// Description:

// Created:

// Author:

// Version:

// Vehicle Project:

LIN_description_file;
LIN_protocol_version = "2.1";
LIN_language_version = "2.1";
LIN_speed = 19.2 kbps;

Nodes {
  Master: BCM, 10 ms, 0.1 ms ;
  Slaves: LFWL, RFWL, LRWL, RRWL;
}
Signals {
  L_BCM_WdwEnable: 1, 0, BCM, LFWL, RFWL, LRWL, RRWL ; //Enable windows movement
  L_BCM_LockCommand: 2, 0, BCM, LFWL, RFWL, LRWL, RRWL ; //Lock Command
  L_BCM_GlobalClose: 2, 0, BCM, LFWL, RFWL, LRWL, RRWL ; //close all windows
  L_BCM_GlobalOpen: 2, 0, BCM, LFWL, RFWL, LRWL, RRWL ; //Open all windows
  L_BCM_ChildLockSt: 1, 0, BCM, LFWL, RFWL, LRWL, RRWL ; //window status of child lock
  L_Pas_Wdw_CenterSwitch: 3, 0, BCM, LFWL, RFWL, LRWL, RRWL ; //Center switch status of passenger window
  L_RLD_Wdw_CenterSwitch: 3, 0, BCM, LFWL, RFWL, LRWL, RRWL ; //Center switch status of Rear Left window
  L_RRD_Wdw_CenterSwitch: 3, 0, BCM, LFWL, RFWL, LRWL, RRWL ; //Center switch status of Rear Right window
  L_Drv_ControlCommand: 7, 127, BCM, LFWL, RFWL, LRWL, RRWL ; //driver window control command
  L_Pas_ControlCommand: 7, 127, BCM, LFWL, RFWL, LRWL, RRWL ; //passenger window control command
  L_RLD_ControlCommand: 7, 127, BCM, LFWL, RFWL, LRWL, RRWL ; //Rear Left window control command
  L_RRD_ControlCommand: 7, 127, BCM, LFWL, RFWL, LRWL, RRWL ; //Rear Right window control command
  L_EMS_EngStatus: 3, 0, BCM, LFWL, RFWL, LRWL, RRWL ; //Engine running status

  L_PEPS_PowerModeValidity: 2, 0, BCM, LFWL, RFWL, LRWL, RRWL; //PEPS Power Distribution StatusValidity bit
  L_PEPS_PowerMode: 3, 0, BCM, LFWL, RFWL, LRWL, RRWL ; //PEPS Power Distribution Status
  L_BCM_VehicleSpeed: 13, 0, BCM, LFWL, RFWL, LRWL, RRWL ; //VehicleSpeed
  L_BCM_OutdoorTemp: 8, 120, BCM, LFWL, RFWL, LRWL, RRWL ; //outdoor ambient temperature
  L_BCM_VehicleType_Reserved: 3, 7, BCM, LFWL, RFWL, LRWL, RRWL ; //With this value the vehicle type is coded

  L_Steer_Whl_Type_Reserved: 2, 3, BCM, LFWL, RFWL, LRWL, RRWL ; //With this value, the steering type is transmitted for the solar sensors. The value is required for the air-conditioning system

  L_Drv_Wdw_Running_Sts: 3, 0, LFWL, BCM ; //Running status of driver window
  L_Drv_Wdw_CenterSwitch: 3, 0, LFWL, BCM ; //Center switch status of driver window
  L_Drv_Wdw_PositionSts: 2, 0, LFWL, BCM ; //Position status of driver window
  L_Drv_Val_Wdw_Opened: 7, 127, LFWL, BCM ; //Window Opened Value
  L_Drv_HALL_Error: 1, 0, LFWL, BCM ; //Hall Sensor Error
  L_Drv_Motor_Relay_Error: 1, 0, LFWL, BCM ; //Motor relay Error
  L_Drv_OverHeat_Protect: 1, 0, LFWL, BCM ; //OverHeat Protect
  L_Drv_Wdw_Init: 1, 0, LFWL, BCM ; //ECU Initialization
  DDAPWL_01_LIN_Response_Error: 1, 0, LFWL, BCM ; //LIN Communication ERROR
  L_Drv_UnderVoltage: 1, 0, LFWL, BCM ; //Driver window under volt
  L_Drv_OverVoltage: 1, 0, LFWL, BCM ; //Driver window over volt
  L_Drv_Wdw_OD_Sts: 1, 0, LFWL, BCM ; //Obstacle detection status
  L_Drv_Wdw_Obs_InhibitSts: 1, 0, LFWL, BCM ; //Obstacle inhibit status
  L_Pas_Wdw_Running_Sts: 3, 0, RFWL, BCM ; //Running status of passager window
  L_Pas_Wdw_LocalSwitch: 3, 0, RFWL, BCM ; //Local switch status of passager window
  L_Pas_Wdw_PositionSts: 2, 0, RFWL, BCM ; //Position status of passager window
  L_Pas_Val_Wdw_Opened: 7, 127, RFWL, BCM ; //Window Opened Value
  L_Pas_HALL_Error: 1, 0, RFWL, BCM ; //Hall Sensor Error
  L_Pas_Motor_Relay_Error: 1, 0, RFWL, BCM ; //Motor relay Error
  L_Pas_OverHeat_Protect: 1, 0, RFWL, BCM ; //OverHeat Protect
  L_Pas_Wdw_Init: 1, 0, RFWL, BCM ; //ECU Initialization
  PDAPWL_01_LIN_Response_Error: 1, 0, RFWL, BCM ; //LIN Communication ERROR
  L_Pas_UnderVoltage: 1, 0, RFWL, BCM ; //Passenger window under volt
  L_Pas_OverVoltage: 1, 0, RFWL, BCM ; //Passenger window over volt
  L_Pas_Wdw_OD_Sts: 1, 0, RFWL, BCM ; //Obstacle detection status
  L_Pas_Wdw_Obs_InhibitSts: 1, 0, RFWL, BCM ; //Obstacle inhibit status
  L_RLD_Wdw_Running_Sts: 3, 0, LRWL, BCM ; //Running status of Rear Left window
  L_RLD_Wdw_LocalSwitch: 3, 0, LRWL, BCM ; //Local switch status of Rear Left window
  L_RLD_Wdw_PositionSts: 2, 0, LRWL, BCM ; //Position status of Rear Left window
  L_RLD_Val_Wdw_Opened: 7, 127, LRWL, BCM ; //Window Opened Value
  L_RLD_HALL_Error: 1, 0, LRWL, BCM ; //Hall Sensor Error
  L_RLD_Motor_Relay_Error: 1, 0, LRWL, BCM ; //Motor relay Error
  L_RLD_OverHeat_Protect: 1, 0, LRWL, BCM ; //OverHeat Protect
  L_RLD_Wdw_Init: 1, 0, LRWL, BCM ; //ECU Initialization
  RLAPWL_01_LIN_Response_Error: 1, 0, LRWL, BCM ; //LIN Communication ERROR
  L_RLUnderVoltage: 1, 0, LRWL, BCM ; //Rear Left window under volt
  L_RLOverVoltage: 1, 0, LRWL, BCM ; //Rear Left window over volt
  L_RLD_Wdw_OD_Sts: 1, 0, LRWL, BCM ; //Obstacle detection status
  L_RLD_Wdw_Obs_InhibitSts: 1, 0, LRWL, BCM ; //Obstacle inhibit status
  L_RRD_Wdw_Running_Sts: 3, 0, RRWL, BCM ; //Running status of Rear Right window
  L_RRD_Wdw_LocalSwitch: 3, 0, RRWL, BCM ; //Local switch status of Rear Right window
  L_RRD_Wdw_PositionSts: 2, 0, RRWL, BCM ; //Position status of Rear Right window
  L_RRD_Val_Wdw_Opened: 7, 127, RRWL, BCM ; //Window Opened Value
  L_RRD_SHALL_Error: 1, 0, RRWL, BCM ; //Hall Sensor Error
  L_RRD_SMotor_Relay_Error: 1, 0, RRWL, BCM ; //Motor relay Error
  L_RRD_SOverHeat_Protect: 1, 0, RRWL, BCM ; //OverHeat Protect
  L_RRD_Wdw_Init: 1, 0, RRWL, BCM ; //ECU Initialization
  RRAPWL_01_LIN_Response_Error: 1, 0, RRWL, BCM ; //LIN Communication ERROR
  L_RRUnderVoltage: 1, 0, RRWL, BCM ; //Rear Right window under volt
  L_RROverVoltage: 1, 0, RRWL, BCM ; //Rear Right window over volt
  L_RRD_Wdw_OD_Sts: 1, 0, RRWL, BCM ; //Obstacle detection status
  L_RRD_Wdw_Obs_InhibitSts: 1, 0, RRWL, BCM ; //Obstacle inhibit status
}

Frames {
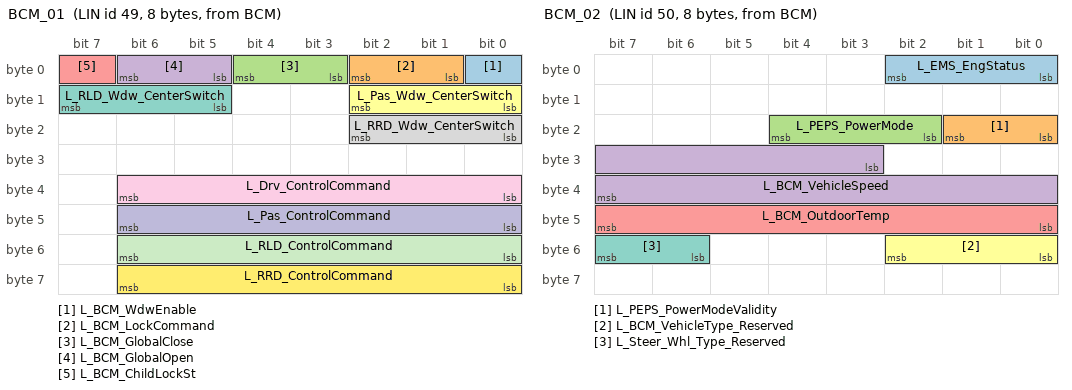
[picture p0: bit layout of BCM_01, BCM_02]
  BCM_01: 49, BCM, 8 {
    L_BCM_WdwEnable, 0 ;
    L_BCM_LockCommand, 1 ;
    L_BCM_GlobalClose, 3 ;
    L_BCM_GlobalOpen, 5 ;
    L_BCM_ChildLockSt, 7 ;
    L_Pas_Wdw_CenterSwitch, 8 ;
    L_RLD_Wdw_CenterSwitch, 13 ;
    L_RRD_Wdw_CenterSwitch, 16 ;
    L_Drv_ControlCommand, 32 ;
    L_Pas_ControlCommand, 40 ;
    L_RLD_ControlCommand, 48 ;
    L_RRD_ControlCommand, 56 ;
  }
  BCM_02: 50, BCM, 8 {
    L_EMS_EngStatus, 0 ;

    L_PEPS_PowerModeValidity, 16 ;
    L_PEPS_PowerMode, 18 ;

    L_BCM_VehicleSpeed, 27 ;
    L_BCM_OutdoorTemp, 40 ;
    L_BCM_VehicleType_Reserved, 48 ;

    L_Steer_Whl_Type_Reserved, 54 ;

  }

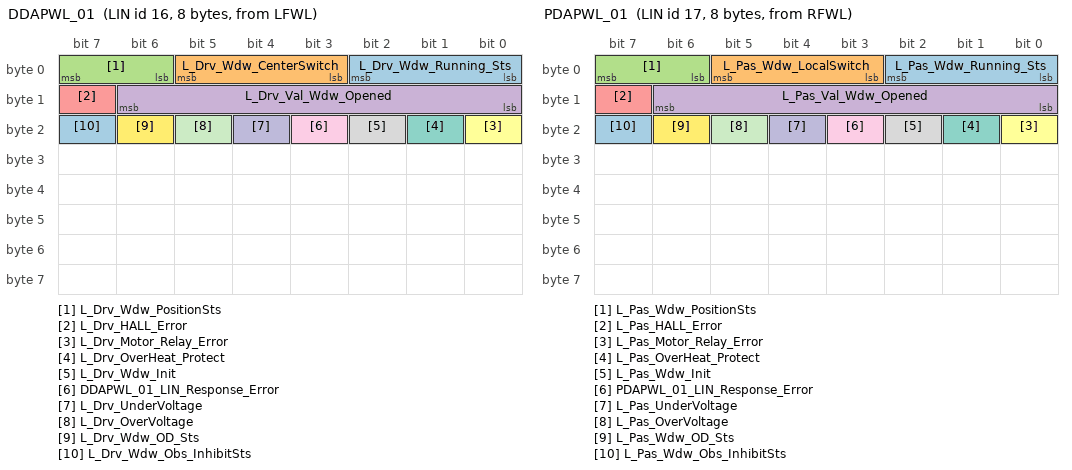
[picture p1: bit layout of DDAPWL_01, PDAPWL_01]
  DDAPWL_01: 16, LFWL, 8 {
    L_Drv_Wdw_Running_Sts, 0 ;
    L_Drv_Wdw_CenterSwitch, 3 ;
    L_Drv_Wdw_PositionSts, 6 ;
    L_Drv_Val_Wdw_Opened, 8 ;
    L_Drv_HALL_Error, 15 ;
    L_Drv_Motor_Relay_Error, 16 ;
    L_Drv_OverHeat_Protect, 17 ;
    L_Drv_Wdw_Init, 18 ;
    DDAPWL_01_LIN_Response_Error, 19 ;
    L_Drv_UnderVoltage, 20 ;
    L_Drv_OverVoltage, 21 ;
    L_Drv_Wdw_OD_Sts, 22 ;
    L_Drv_Wdw_Obs_InhibitSts, 23 ;
  }
  PDAPWL_01: 17, RFWL, 8 {
    L_Pas_Wdw_Running_Sts, 0 ;
    L_Pas_Wdw_LocalSwitch, 3 ;
    L_Pas_Wdw_PositionSts, 6 ;
    L_Pas_Val_Wdw_Opened, 8 ;
    L_Pas_HALL_Error, 15 ;
    L_Pas_Motor_Relay_Error, 16 ;
    L_Pas_OverHeat_Protect, 17 ;
    L_Pas_Wdw_Init, 18 ;
    PDAPWL_01_LIN_Response_Error, 19 ;
    L_Pas_UnderVoltage, 20 ;
    L_Pas_OverVoltage, 21 ;
    L_Pas_Wdw_OD_Sts, 22 ;
    L_Pas_Wdw_Obs_InhibitSts, 23 ;
  }
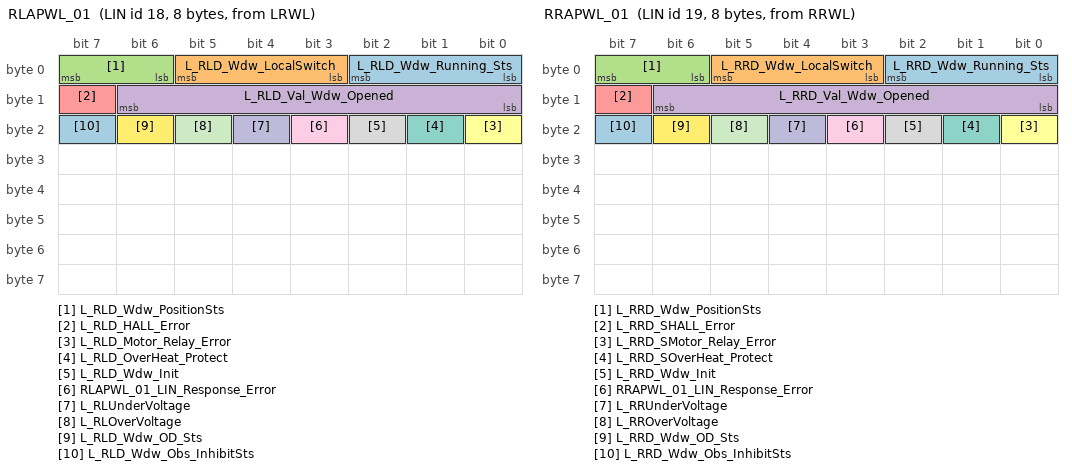
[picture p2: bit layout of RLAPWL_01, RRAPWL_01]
  RLAPWL_01: 18, LRWL, 8 {
    L_RLD_Wdw_Running_Sts, 0 ;
    L_RLD_Wdw_LocalSwitch, 3 ;
    L_RLD_Wdw_PositionSts, 6 ;
    L_RLD_Val_Wdw_Opened, 8 ;
    L_RLD_HALL_Error, 15 ;
    L_RLD_Motor_Relay_Error, 16 ;
    L_RLD_OverHeat_Protect, 17 ;
    L_RLD_Wdw_Init, 18 ;
    RLAPWL_01_LIN_Response_Error, 19 ;
    L_RLUnderVoltage, 20 ;
    L_RLOverVoltage, 21 ;
    L_RLD_Wdw_OD_Sts, 22 ;
    L_RLD_Wdw_Obs_InhibitSts, 23 ;
  }
  RRAPWL_01: 19, RRWL, 8 {
    L_RRD_Wdw_Running_Sts, 0 ;
    L_RRD_Wdw_LocalSwitch, 3 ;
    L_RRD_Wdw_PositionSts, 6 ;
    L_RRD_Val_Wdw_Opened, 8 ;
    L_RRD_SHALL_Error, 15 ;
    L_RRD_SMotor_Relay_Error, 16 ;
    L_RRD_SOverHeat_Protect, 17 ;
    L_RRD_Wdw_Init, 18 ;
    RRAPWL_01_LIN_Response_Error, 19 ;
    L_RRUnderVoltage, 20 ;
    L_RROverVoltage, 21 ;
    L_RRD_Wdw_OD_Sts, 22 ;
    L_RRD_Wdw_Obs_InhibitSts, 23 ;
  }
}

Node_attributes {
  LFWL{
    LIN_protocol = "2.1" ;
    configured_NAD = 0x10 ;
    product_id = 0x0, 0x0, 0 ;
    response_error = DDAPWL_01_LIN_Response_Error ;
    P2_min = 50 ms ;
    ST_min = 0 ms ;
    N_As_timeout = 1000 ms ;
    N_Cr_timeout = 1000 ms ;
    configurable_frames {
      DDAPWL_01;
      BCM_01 ;
      BCM_02 ;
    }
  }
  LRWL{
    LIN_protocol = "2.1" ;
    configured_NAD = 0x12 ;
    product_id = 0x0, 0x0, 0 ;
    response_error = RLAPWL_01_LIN_Response_Error ;
    P2_min = 50 ms ;
    ST_min = 0 ms ;
    N_As_timeout = 1000 ms ;
    N_Cr_timeout = 1000 ms ;
    configurable_frames {
      RLAPWL_01 ;
      BCM_01;
      BCM_02;
    }
  }
  RFWL{
    LIN_protocol = "2.1" ;
    configured_NAD = 0x11 ;
    product_id = 0x0, 0x0, 0 ;
    response_error = PDAPWL_01_LIN_Response_Error ;
    P2_min = 50 ms ;
    ST_min = 0 ms ;
    N_As_timeout = 1000 ms ;
    N_Cr_timeout = 1000 ms ;
    configurable_frames {
      PDAPWL_01 ;
      BCM_01 ;
      BCM_02 ;
    }
  }
  RRWL{
    LIN_protocol = "2.1" ;
    configured_NAD = 0x13 ;
    product_id = 0x0, 0x0, 0 ;
    response_error = RRAPWL_01_LIN_Response_Error ;
    P2_min = 50 ms ;
    ST_min = 0 ms ;
    N_As_timeout = 1000 ms ;
    N_Cr_timeout = 1000 ms ;
    configurable_frames {
      RRAPWL_01;
      BCM_01 ;
      BCM_02 ;
    }
  }

}

Schedule_tables {
Dynamic {
    BCM_01 delay 10 ms ;//49 31
    BCM_02 delay 30 ms ;//50 32

    DDAPWL_01 delay 10 ms ;//16 10
    BCM_01 delay 10 ms ;//49 31
    BCM_02 delay 10 ms ;//50 32
    PDAPWL_01 delay 10 ms ;//17 11
    RLAPWL_01 delay 10 ms ;//18 12
    RRAPWL_01 delay 10 ms ;//19 13
  }
}
Signal_encoding_types {
  L_BCM_WdwEnable {
    physical_value, 0x0, 0x1, 1, 0, "bit" ;
    logical_value, 0, "Inhibit" ;
    logical_value, 1, "Normal" ;
  }
  L_BCM_LockCommand {
    physical_value, 0x0, 0x3, 1, 0, "bit" ;
    logical_value, 0, "No command" ;
    logical_value, 1, "All door lock" ;
    logical_value, 2, "All door unlock" ;
    logical_value, 3, "Reserved" ;
  }
  L_BCM_GlobalClose {
    physical_value, 0x0, 0x3, 1, 0, "bit" ;
    logical_value, 0, "No action" ;
    logical_value, 1, "Global Close" ;
    logical_value, 2, "Reserved" ;
    logical_value, 3, "Reserved" ;
  }
  L_BCM_GlobalOpen {
    physical_value, 0x0, 0x3, 1, 0, "bit" ;
    logical_value, 0, "No action" ;
    logical_value, 1, "Global Open" ;
    logical_value, 2, "Reserved" ;
    logical_value, 3, "Reserved" ;
  }
  L_BCM_ChildLockSt {
    physical_value, 0x0, 0x1, 1, 0, "bit" ;
    logical_value, 0, "Unlock" ;
    logical_value, 1, "Lock" ;
  }
  L_Pas_Wdw_CenterSwitch {
    physical_value, 0x0, 0x7, 1, 0, "bit" ;
    logical_value, 0, "Inactive" ;
    logical_value, 1, "Manual Up" ;
    logical_value, 2, "Manual Down" ;
    logical_value, 3, "Auto Up" ;
    logical_value, 4, "Auto Down" ;
    logical_value, 5, "Reserved" ;
    logical_value, 6, "Reserved" ;
    logical_value, 7, "Error" ;
  }
  L_RLD_Wdw_CenterSwitch {
    physical_value, 0x0, 0x7, 1, 0, "bit" ;
    logical_value, 0, "Inactive" ;
    logical_value, 1, "Manual Up" ;
    logical_value, 2, "Manual Down" ;
    logical_value, 3, "Auto Up" ;
    logical_value, 4, "Auto Down" ;
    logical_value, 5, "Reserved" ;
    logical_value, 6, "Reserved" ;
    logical_value, 7, "Error" ;
  }
  L_RRD_Wdw_CenterSwitch {
    physical_value, 0x0, 0x7, 1, 0, "bit" ;
    logical_value, 0, "Inactive" ;
    logical_value, 1, "Manual Up" ;
    logical_value, 2, "Manual Down" ;
    logical_value, 3, "Auto Up" ;
    logical_value, 4, "Auto Down" ;
    logical_value, 5, "Reserved" ;
    logical_value, 6, "Reserved" ;
    logical_value, 7, "Error" ;
  }
  L_Drv_ControlCommand {
    physical_value, 0x0, 0x64, 1, 0, "%" ;
    logical_value, 127, "No Request" ;
  }
  L_Pas_ControlCommand {
    physical_value, 0x0, 0x64, 1, 0, "%" ;
    logical_value, 127, "No Request" ;
  }
  L_RLD_ControlCommand {
    physical_value, 0x0, 0x64, 1, 0, "%" ;
    logical_value, 127, "No Request" ;
  }
  L_RRD_ControlCommand {
    physical_value, 0x0, 0x64, 1, 0, "%" ;
    logical_value, 127, "No Request" ;
  }
  L_EMS_EngStatus {
    physical_value, 0x0, 0x7, 1, 0, "bit" ;
    logical_value, 0, "Engine Stop" ;
    logical_value, 1, "Cranking" ;
    logical_value, 2, "Reserved" ;
    logical_value, 3, "Running" ;
    logical_value, 4, "Reserved" ;
    logical_value, 5, "Reserved" ;
    logical_value, 6, "Reserved" ;
    logical_value, 7, "Fault" ;
  }

  L_PEPS_PowerModeValidity {
    physical_value, 0x0, 0x3, 1, 0, "bit" ;
    logical_value, 0, "Not available" ;
    logical_value, 1, "Invalid" ;
    logical_value, 2, "Valid" ;
    logical_value, 3, "Reserved" ;
  }
  L_PEPS_PowerMode {
    physical_value, 0x0, 0x7, 1, 0, "bit" ;
    logical_value, 0, "OFF" ;
    logical_value, 1, "ACC" ;
    logical_value, 2, "ON" ;
    logical_value, 3, "Reserved" ;
    logical_value, 4, "START" ;
  }

  L_BCM_VehicleSpeed {
    physical_value, 0x0, 0x1FFE, 0.05625, 0, "KPH" ;
    logical_value, 8191, "Invalid" ;
  }
  L_BCM_OutdoorTemp {
    physical_value, 0x0, 0xC8, 0.5, -40, "°„C" ;
    logical_value, 201, "Invalid" ;
  }
  L_BCM_VehicleType_Reserved {
    physical_value, 0x0, 0x7, 1, 0, "bit" ;
    logical_value, 0, "GC-1" ;
    logical_value, 1, "NL-1" ;
    logical_value, 2, "KC-1" ;
    logical_value, 3, "FE-5/7" ;
    logical_value, 4, "KC-2" ;
    logical_value, 5, "FE-6" ;
    logical_value, 6, "Reserved" ;
    logical_value, 7, "Invalid" ;
  }

  L_Steer_Whl_Type_Reserved {
    physical_value, 0x0, 0x3, 1, 0, "bit" ;
    logical_value, 0, "Left-hand drive" ;
    logical_value, 1, "Right-hand drive" ;
    logical_value, 2, "Reserved" ;
    logical_value, 3, "Invalid" ;
  }

  L_Drv_Wdw_Running_Sts {
    physical_value, 0x0, 0x7, 1, 0, "bit" ;
    logical_value, 0, "Window stop" ;
    logical_value, 1, "Manual Up" ;
    logical_value, 2, "Manual Down" ;
    logical_value, 3, "Auto Up" ;
    logical_value, 4, "Auto Down" ;
  }
  L_Drv_Wdw_CenterSwitch {
    physical_value, 0x0, 0x7, 1, 0, "bit" ;
    logical_value, 0, "Inactive" ;
    logical_value, 1, "Manual Up" ;
    logical_value, 2, "Manual Down" ;
    logical_value, 3, "Auto Up" ;
    logical_value, 4, "Auto Down" ;
    logical_value, 5, "Reserved" ;
    logical_value, 6, "Reserved" ;
    logical_value, 7, "Error" ;
  }
  L_Drv_Wdw_PositionSts {
    physical_value, 0x0, 0x3, 1, 0, "bit" ;
    logical_value, 0, "Middle position" ;
    logical_value, 1, "Complete Open" ;
    logical_value, 2, "Complete Close" ;
    logical_value, 3, "Invalid" ;
  }
  L_Drv_Val_Wdw_Opened {
    physical_value, 0x0, 0x64, 1, 0, "%" ;
    logical_value, 127, "Invalid" ;
  }
  L_Drv_HALL_Error {
    physical_value, 0x0, 0x1, 1, 0, "bit" ;
    logical_value, 0, "Normal" ;
    logical_value, 1, "Error" ;
  }
  L_Drv_Motor_Relay_Error {
    physical_value, 0x0, 0x1, 1, 0, "bit" ;
    logical_value, 0, "Normal" ;
    logical_value, 1, "Error" ;
  }
  L_Drv_OverHeat_Protect {
    physical_value, 0x0, 0x1, 1, 0, "bit" ;
    logical_value, 0, "Inactive" ;
    logical_value, 1, "Active" ;
  }
  L_Drv_Wdw_Init {
    physical_value, 0x0, 0x1, 1, 0, "bit" ;
    logical_value, 0, "Window init incomplete" ;
    logical_value, 1, "Window init complete" ;
  }
  DDAPWL_01_LIN_Response_Error {
    physical_value, 0x0, 0x1, 1, 0, "bit" ;
    logical_value, 0, "Normal" ;
    logical_value, 1, "Error" ;
  }
  L_Drv_UnderVoltage {
    physical_value, 0x0, 0x1, 1, 0, "bit" ;
    logical_value, 0, "Normal" ;
    logical_value, 1, "UnderVoltage" ;
  }
  L_Drv_OverVoltage {
    physical_value, 0x0, 0x1, 1, 0, "bit" ;
    logical_value, 0, "Normal" ;
    logical_value, 1, "OverVoltage" ;
  }
  L_Drv_Wdw_OD_Sts {
    physical_value, 0x0, 0x1, 1, 0, "bit" ;
    logical_value, 0, "Non anti-pinch status" ;
    logical_value, 1, "In Anti-pinch status" ;
  }
  L_Drv_Wdw_Obs_InhibitSts {
    physical_value, 0x0, 0x1, 1, 0, "bit" ;
    logical_value, 0, "Not Obs Inhibit status" ;
    logical_value, 1, "Obs Inhibit status" ;
  }
  L_Pas_Wdw_Running_Sts {
    physical_value, 0x0, 0x7, 1, 0, "bit" ;
    logical_value, 0, "Window stop" ;
    logical_value, 1, "Manual Up" ;
    logical_value, 2, "Manual Down" ;
    logical_value, 3, "Auto Up" ;
    logical_value, 4, "Auto Down" ;
  }
  L_Pas_Wdw_LocalSwitch {
    physical_value, 0x0, 0x7, 1, 0, "bit" ;
    logical_value, 0, "Inactive" ;
    logical_value, 1, "Manual Up" ;
    logical_value, 2, "Manual Down" ;
    logical_value, 3, "Auto Up" ;
    logical_value, 4, "Auto Down" ;
    logical_value, 5, "Reserved" ;
    logical_value, 6, "Reserved" ;
    logical_value, 7, "Error" ;
  }
  L_Pas_Wdw_PositionSts {
    physical_value, 0x0, 0x3, 1, 0, "bit" ;
    logical_value, 0, "Middle position" ;
    logical_value, 1, "Complete Open" ;
    logical_value, 2, "Complete Close" ;
    logical_value, 3, "Invalid" ;
  }
  L_Pas_Val_Wdw_Opened {
    physical_value, 0x0, 0x64, 1, 0, "%" ;
    logical_value, 127, "Invalid" ;
  }
  L_Pas_HALL_Error {
    physical_value, 0x0, 0x1, 1, 0, "bit" ;
    logical_value, 0, "Normal" ;
    logical_value, 1, "Error" ;
  }
  L_Pas_Motor_Relay_Error {
    physical_value, 0x0, 0x1, 1, 0, "bit" ;
    logical_value, 0, "Normal" ;
    logical_value, 1, "Error" ;
  }
  L_Pas_OverHeat_Protect {
    physical_value, 0x0, 0x1, 1, 0, "bit" ;
    logical_value, 0, "Inactive" ;
    logical_value, 1, "Active" ;
  }
  L_Pas_Wdw_Init {
    physical_value, 0x0, 0x1, 1, 0, "bit" ;
    logical_value, 0, "Window init incomplete" ;
    logical_value, 1, "Window init complete" ;
  }
  PDAPWL_01_LIN_Response_Error {
    physical_value, 0x0, 0x1, 1, 0, "bit" ;
    logical_value, 0, "Normal" ;
    logical_value, 1, "Error" ;
  }
  L_Pas_UnderVoltage {
    physical_value, 0x0, 0x1, 1, 0, "bit" ;
    logical_value, 0, "Normal" ;
    logical_value, 1, "UnderVoltage" ;
  }
  L_Pas_OverVoltage {
    physical_value, 0x0, 0x1, 1, 0, "bit" ;
    logical_value, 0, "Normal" ;
    logical_value, 1, "OverVoltage" ;
  }
  L_Pas_Wdw_OD_Sts {
    physical_value, 0x0, 0x1, 1, 0, "bit" ;
    logical_value, 0, "Non anti-pinch status" ;
    logical_value, 1, "In Anti-pinch status" ;
  }
  L_Pas_Wdw_Obs_InhibitSts {
    physical_value, 0x0, 0x1, 1, 0, "bit" ;
    logical_value, 0, "Not Obs Inhibit status" ;
    logical_value, 1, "Obs Inhibit status" ;
  }
  L_RLD_Wdw_Running_Sts {
    physical_value, 0x0, 0x7, 1, 0, "bit" ;
    logical_value, 0, "Window stop" ;
    logical_value, 1, "Manual Up" ;
    logical_value, 2, "Manual Down" ;
    logical_value, 3, "Auto Up" ;
    logical_value, 4, "Auto Down" ;
  }
  L_RLD_Wdw_LocalSwitch {
    physical_value, 0x0, 0x7, 1, 0, "bit" ;
    logical_value, 0, "Inactive" ;
    logical_value, 1, "Manual Up" ;
    logical_value, 2, "Manual Down" ;
    logical_value, 3, "Auto Up" ;
    logical_value, 4, "Auto Down" ;
    logical_value, 5, "Reserved" ;
    logical_value, 6, "Reserved" ;
    logical_value, 7, "Error" ;
  }
  L_RLD_Wdw_PositionSts {
    physical_value, 0x0, 0x3, 1, 0, "bit" ;
    logical_value, 0, "Middle position" ;
    logical_value, 1, "Complete Open" ;
    logical_value, 2, "Complete Close" ;
    logical_value, 3, "Invalid" ;
  }
  L_RLD_Val_Wdw_Opened {
    physical_value, 0x0, 0x64, 1, 0, "%" ;
    logical_value, 127, "Invalid" ;
  }
  L_RLD_HALL_Error {
    physical_value, 0x0, 0x1, 1, 0, "bit" ;
    logical_value, 0, "Normal" ;
    logical_value, 1, "Error" ;
  }
  L_RLD_Motor_Relay_Error {
    physical_value, 0x0, 0x1, 1, 0, "bit" ;
    logical_value, 0, "Normal" ;
    logical_value, 1, "Error" ;
  }
  L_RLD_OverHeat_Protect {
    physical_value, 0x0, 0x1, 1, 0, "bit" ;
    logical_value, 0, "Inactive" ;
    logical_value, 1, "Active" ;
  }
  L_RLD_Wdw_Init {
    physical_value, 0x0, 0x1, 1, 0, "bit" ;
    logical_value, 0, "Window init incomplete" ;
    logical_value, 1, "Window init complete" ;
  }
  RLAPWL_01_LIN_Response_Error {
    physical_value, 0x0, 0x1, 1, 0, "bit" ;
    logical_value, 0, "Normal" ;
    logical_value, 1, "Error" ;
  }
  L_RLUnderVoltage {
    physical_value, 0x0, 0x1, 1, 0, "bit" ;
    logical_value, 0, "Normal" ;
    logical_value, 1, "UnderVoltage" ;
  }
  L_RLOverVoltage {
    physical_value, 0x0, 0x1, 1, 0, "bit" ;
    logical_value, 0, "Normal" ;
    logical_value, 1, "OverVoltage" ;
  }
  L_RLD_Wdw_OD_Sts {
    physical_value, 0x0, 0x1, 1, 0, "bit" ;
    logical_value, 0, "Non anti-pinch status" ;
    logical_value, 1, "In Anti-pinch status" ;
  }
  L_RLD_Wdw_Obs_InhibitSts {
    physical_value, 0x0, 0x1, 1, 0, "bit" ;
    logical_value, 0, "Not Obs Inhibit status" ;
    logical_value, 1, "Obs Inhibit status" ;
  }
  L_RRD_Wdw_Running_Sts {
    physical_value, 0x0, 0x7, 1, 0, "bit" ;
    logical_value, 0, "Window stop" ;
    logical_value, 1, "Manual Up" ;
    logical_value, 2, "Manual Down" ;
    logical_value, 3, "Auto Up" ;
    logical_value, 4, "Auto Down" ;
  }
  L_RRD_Wdw_LocalSwitch {
    physical_value, 0x0, 0x7, 1, 0, "bit" ;
    logical_value, 0, "Inactive" ;
    logical_value, 1, "Manual Up" ;
    logical_value, 2, "Manual Down" ;
    logical_value, 3, "Auto Up" ;
    logical_value, 4, "Auto Down" ;
    logical_value, 5, "Reserved" ;
    logical_value, 6, "Reserved" ;
    logical_value, 7, "Error" ;
  }
  L_RRD_Wdw_PositionSts {
    physical_value, 0x0, 0x3, 1, 0, "bit" ;
    logical_value, 0, "Middle position" ;
    logical_value, 1, "Complete Open" ;
    logical_value, 2, "Complete Close" ;
    logical_value, 3, "Invalid" ;
  }
  L_RRD_Val_Wdw_Opened {
    physical_value, 0x0, 0x64, 1, 0, "%" ;
    logical_value, 127, "Invalid" ;
  }
  L_RRD_SHALL_Error {
    physical_value, 0x0, 0x1, 1, 0, "bit" ;
    logical_value, 0, "Normal" ;
    logical_value, 1, "Error" ;
  }
  L_RRD_SMotor_Relay_Error {
    physical_value, 0x0, 0x1, 1, 0, "bit" ;
    logical_value, 0, "Normal" ;
    logical_value, 1, "Error" ;
  }
  L_RRD_SOverHeat_Protect {
    physical_value, 0x0, 0x1, 1, 0, "bit" ;
    logical_value, 0, "Inactive" ;
    logical_value, 1, "Active" ;
  }
  L_RRD_Wdw_Init {
    physical_value, 0x0, 0x1, 1, 0, "bit" ;
    logical_value, 0, "Window init incomplete" ;
    logical_value, 1, "Window init complete" ;
  }
  RRAPWL_01_LIN_Response_Error {
    physical_value, 0x0, 0x1, 1, 0, "bit" ;
    logical_value, 0, "Normal" ;
    logical_value, 1, "Error" ;
  }
  L_RRUnderVoltage {
    physical_value, 0x0, 0x1, 1, 0, "bit" ;
    logical_value, 0, "Normal" ;
    logical_value, 1, "UnderVoltage" ;
  }
  L_RROverVoltage {
    physical_value, 0x0, 0x1, 1, 0, "bit" ;
    logical_value, 0, "Normal" ;
    logical_value, 1, "OverVoltage" ;
  }
  L_RRD_Wdw_OD_Sts {
    physical_value, 0x0, 0x1, 1, 0, "bit" ;
    logical_value, 0, "Non anti-pinch status" ;
    logical_value, 1, "In Anti-pinch status" ;
  }
  L_RRD_Wdw_Obs_InhibitSts {
    physical_value, 0x0, 0x1, 1, 0, "bit" ;
    logical_value, 0, "Not Obs Inhibit status" ;
    logical_value, 1, "Obs Inhibit status" ;
  }
}
